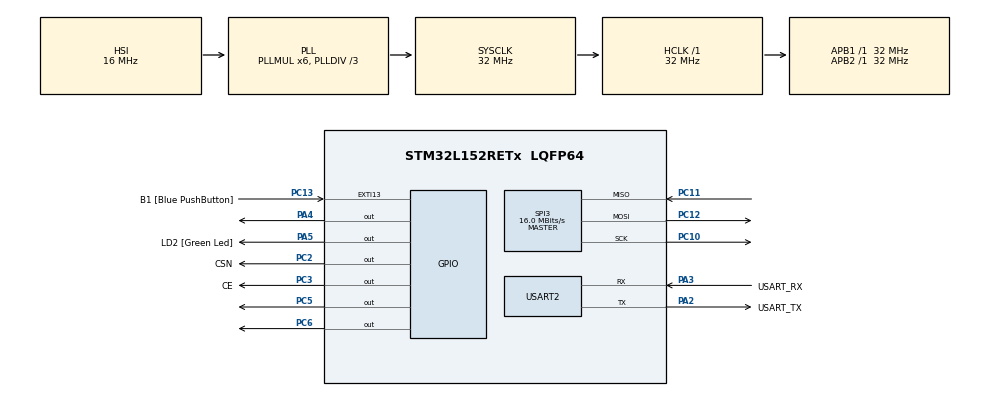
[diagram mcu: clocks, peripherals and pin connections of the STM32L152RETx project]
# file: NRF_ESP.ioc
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Mcu.Family=STM32L1
Mcu.Name=STM32L152RETx
Mcu.Package=LQFP64
NVIC.PriorityGroup=NVIC_PRIORITYGROUP_0
NVIC.SPI3_IRQn=true\:0\:0\:false\:false\:true\:true\:true\:true
PA13.GPIO_Label=TMS
PA13.Mode=Serial_Wire
PA13.Signal=SYS_JTMS-SWDIO
PA14.GPIO_Label=TCK
PA14.Mode=Serial_Wire
PA14.Signal=SYS_JTCK-SWCLK
PA2.GPIO_Label=USART_TX
PA2.Mode=Asynchronous
PA2.Signal=USART2_TX
PA3.GPIO_Label=USART_RX
PA3.Mode=Asynchronous
PA3.Signal=USART2_RX
PA4.Signal=GPIO_Output
PA5.GPIO_Label=LD2 [Green Led]
PA5.Signal=GPIO_Output
PB3.GPIO_Label=SWO
PB3.Signal=SYS_JTDO-TRACESWO
PC10.Mode=Full_Duplex_Master
PC10.Signal=SPI3_SCK
PC11.Mode=Full_Duplex_Master
PC11.Signal=SPI3_MISO
PC12.Mode=Full_Duplex_Master
PC12.Signal=SPI3_MOSI
PC13-WKUP2.GPIO_Label=B1 [Blue PushButton]
PC13-WKUP2.Signal=GPXTI13
PC14-OSC32_IN.Mode=LSE-External-Oscillator
PC14-OSC32_IN.Signal=RCC_OSC32_IN
PC15-OSC32_OUT.Mode=LSE-External-Oscillator
PC15-OSC32_OUT.Signal=RCC_OSC32_OUT
PC2.GPIO_Label=CSN
PC2.Signal=GPIO_Output
PC3.GPIO_Label=CE
PC3.Signal=GPIO_Output
PC5.Signal=GPIO_Output
PC6.Signal=GPIO_Output
PH0-OSC_IN.Mode=HSE-External-Clock-Source
PH0-OSC_IN.Signal=RCC_OSC_IN
PH1-OSC_OUT.Signal=RCC_OSC_OUT
ProjectManager.HeapSize=0x200
ProjectManager.StackSize=0x400
ProjectManager.TargetToolchain=STM32CubeIDE
RCC.48MHZClocksFreq_Value=48000000
RCC.AHBFreq_Value=32000000
RCC.APB1Freq_Value=32000000
RCC.APB1TimFreq_Value=32000000
RCC.APB2Freq_Value=32000000
RCC.APB2TimFreq_Value=32000000
RCC.HCLKFreq_Value=32000000
RCC.HSE_VALUE=8000000
RCC.HSI_VALUE=16000000
RCC.MSI_VALUE=2097000
RCC.PLLDIV=RCC_PLL_DIV3
RCC.PLLMUL=RCC_PLL_MUL6
RCC.RTCClockSelectionVirtual=RCC_RTCCLKSOURCE_LSE
RCC.SYSCLKFreq_VALUE=32000000
RCC.SYSCLKSource=RCC_SYSCLKSOURCE_PLLCLK
RCC.USBOutput=48000000
RCC.VCOOutputFreq_Value=96000000
SPI3.CalculateBaudRate=16.0 MBits/s
SPI3.Direction=SPI_DIRECTION_2LINES
SPI3.Mode=SPI_MODE_MASTER
SPI3.VirtualType=VM_MASTER
USART2.VirtualMode=VM_ASYNC
board=NUCLEO-L152RE

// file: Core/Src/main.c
/* USER CODE BEGIN Header */
/**
  ******************************************************************************
  * @file           : main.c
  * @brief          : Main program body
  ******************************************************************************
  * @attention
  *
  * Copyright (c) 2024 STMicroelectronics.
  * All rights reserved.
  *
  * This software is licensed under terms that can be found in the LICENSE file
  * in the root directory of this software component.
  * If no LICENSE file comes with this software, it is provided AS-IS.
  *
  ******************************************************************************
  */
/* USER CODE END Header */
#include "main.h"

/* USER CODE BEGIN Includes */
#include "NRF24L01.h"
#include "string.h"
/* USER CODE END Includes */

SPI_HandleTypeDef hspi3;

UART_HandleTypeDef huart2;

void SystemClock_Config(void);
static void MX_GPIO_Init(void);
static void MX_USART2_UART_Init(void);
static void MX_SPI3_Init(void);

/* USER CODE BEGIN 0 */

uint8_t data[50];

uint8_t TxAddress[] = {0xEE,0xDD,0xCC,0xBB,0xAA};
uint8_t TxData[] = "I am From STM32 World\n";

/* USER CODE END 0 */

int main(void)
{

  /* MCU Configuration--------------------------------------------------------*/

  /* Reset of all peripherals, Initializes the Flash interface and the Systick. */
  HAL_Init();

  /* Configure the system clock */
  SystemClock_Config();

  /* Initialize all configured peripherals */
  MX_GPIO_Init();
  MX_USART2_UART_Init();
  MX_SPI3_Init();
  /* USER CODE BEGIN 2 */
  NRF24_Init();

  NRF24_TxMode(TxAddress, 10);

  /* USER CODE END 2 */

  /* Infinite loop */
  while (1)
  {

    /* USER CODE BEGIN 3 */
	  	  if (NRF24_Transmit(TxData) == 1)
	  	  {
	  		  HAL_GPIO_TogglePin(LD2_GPIO_Port, LD2_Pin);
	  		  HAL_UART_Transmit(&huart2 ,TxData , sizeof(TxData) , 100 );
	  	  }

  		  HAL_GPIO_TogglePin(LD2_GPIO_Port, LD2_Pin);
  		  HAL_UART_Transmit(&huart2 ,TxData , sizeof(TxData) , 100 );

	  	  HAL_Delay(1000);

  }
  /* USER CODE END 3 */
}

void SystemClock_Config(void)
{
  RCC_OscInitTypeDef RCC_OscInitStruct = {0};
  RCC_ClkInitTypeDef RCC_ClkInitStruct = {0};

  /** Configure the main internal regulator output voltage
  */
  __HAL_PWR_VOLTAGESCALING_CONFIG(PWR_REGULATOR_VOLTAGE_SCALE1);

  /** Initializes the RCC Oscillators according to the specified parameters
  * in the RCC_OscInitTypeDef structure.
  */
  RCC_OscInitStruct.OscillatorType = RCC_OSCILLATORTYPE_HSI;
  RCC_OscInitStruct.HSIState = RCC_HSI_ON;
  RCC_OscInitStruct.HSICalibrationValue = RCC_HSICALIBRATION_DEFAULT;
  RCC_OscInitStruct.PLL.PLLState = RCC_PLL_ON;
  RCC_OscInitStruct.PLL.PLLSource = RCC_PLLSOURCE_HSI;
  RCC_OscInitStruct.PLL.PLLMUL = RCC_PLL_MUL6;
  RCC_OscInitStruct.PLL.PLLDIV = RCC_PLL_DIV3;
  if (HAL_RCC_OscConfig(&RCC_OscInitStruct) != HAL_OK)
  {
    Error_Handler();
  }

  /** Initializes the CPU, AHB and APB buses clocks
  */
  RCC_ClkInitStruct.ClockType = RCC_CLOCKTYPE_HCLK|RCC_CLOCKTYPE_SYSCLK
                              |RCC_CLOCKTYPE_PCLK1|RCC_CLOCKTYPE_PCLK2;
  RCC_ClkInitStruct.SYSCLKSource = RCC_SYSCLKSOURCE_PLLCLK;
  RCC_ClkInitStruct.AHBCLKDivider = RCC_SYSCLK_DIV1;
  RCC_ClkInitStruct.APB1CLKDivider = RCC_HCLK_DIV1;
  RCC_ClkInitStruct.APB2CLKDivider = RCC_HCLK_DIV1;

  if (HAL_RCC_ClockConfig(&RCC_ClkInitStruct, FLASH_LATENCY_1) != HAL_OK)
  {
    Error_Handler();
  }
}

static void MX_SPI3_Init(void)
{

  /* SPI3 parameter configuration*/
  hspi3.Instance = SPI3;
  hspi3.Init.Mode = SPI_MODE_MASTER;
  hspi3.Init.Direction = SPI_DIRECTION_2LINES;
  hspi3.Init.DataSize = SPI_DATASIZE_8BIT;
  hspi3.Init.CLKPolarity = SPI_POLARITY_LOW;
  hspi3.Init.CLKPhase = SPI_PHASE_1EDGE;
  hspi3.Init.NSS = SPI_NSS_SOFT;
  hspi3.Init.BaudRatePrescaler = SPI_BAUDRATEPRESCALER_2;
  hspi3.Init.FirstBit = SPI_FIRSTBIT_MSB;
  hspi3.Init.TIMode = SPI_TIMODE_DISABLE;
  hspi3.Init.CRCCalculation = SPI_CRCCALCULATION_DISABLE;
  hspi3.Init.CRCPolynomial = 10;
  if (HAL_SPI_Init(&hspi3) != HAL_OK)
  {
    Error_Handler();
  }

}

static void MX_USART2_UART_Init(void)
{

  huart2.Instance = USART2;
  huart2.Init.BaudRate = 115200;
  huart2.Init.WordLength = UART_WORDLENGTH_8B;
  huart2.Init.StopBits = UART_STOPBITS_1;
  huart2.Init.Parity = UART_PARITY_NONE;
  huart2.Init.Mode = UART_MODE_TX_RX;
  huart2.Init.HwFlowCtl = UART_HWCONTROL_NONE;
  huart2.Init.OverSampling = UART_OVERSAMPLING_16;
  if (HAL_UART_Init(&huart2) != HAL_OK)
  {
    Error_Handler();
  }

}

static void MX_GPIO_Init(void)
{
  GPIO_InitTypeDef GPIO_InitStruct = {0};

  /* GPIO Ports Clock Enable */
  __HAL_RCC_GPIOC_CLK_ENABLE();
  __HAL_RCC_GPIOH_CLK_ENABLE();
  __HAL_RCC_GPIOA_CLK_ENABLE();
  __HAL_RCC_GPIOB_CLK_ENABLE();

  /*Configure GPIO pin Output Level */
  HAL_GPIO_WritePin(GPIOC, CSN_Pin|CE_Pin|GPIO_PIN_5|GPIO_PIN_6, GPIO_PIN_RESET);

  /*Configure GPIO pin Output Level */
  HAL_GPIO_WritePin(GPIOA, GPIO_PIN_4|LD2_Pin, GPIO_PIN_RESET);

  /*Configure GPIO pin : B1_Pin */
  GPIO_InitStruct.Pin = B1_Pin;
  GPIO_InitStruct.Mode = GPIO_MODE_IT_RISING;
  GPIO_InitStruct.Pull = GPIO_NOPULL;
  HAL_GPIO_Init(B1_GPIO_Port, &GPIO_InitStruct);

  /*Configure GPIO pins : CSN_Pin CE_Pin PC5 PC6 */
  GPIO_InitStruct.Pin = CSN_Pin|CE_Pin|GPIO_PIN_5|GPIO_PIN_6;
  GPIO_InitStruct.Mode = GPIO_MODE_OUTPUT_PP;
  GPIO_InitStruct.Pull = GPIO_NOPULL;
  GPIO_InitStruct.Speed = GPIO_SPEED_FREQ_LOW;
  HAL_GPIO_Init(GPIOC, &GPIO_InitStruct);

  /*Configure GPIO pins : PA4 LD2_Pin */
  GPIO_InitStruct.Pin = GPIO_PIN_4|LD2_Pin;
  GPIO_InitStruct.Mode = GPIO_MODE_OUTPUT_PP;
  GPIO_InitStruct.Pull = GPIO_NOPULL;
  GPIO_InitStruct.Speed = GPIO_SPEED_FREQ_LOW;
  HAL_GPIO_Init(GPIOA, &GPIO_InitStruct);

}

void Error_Handler(void)
{
  /* USER CODE BEGIN Error_Handler_Debug */
  /* User can add his own implementation to report the HAL error return state */
  __disable_irq();
  while (1)
  {
	  HAL_GPIO_WritePin(GPIOB , LD2_Pin , GPIO_PIN_SET);
  }
  /* USER CODE END Error_Handler_Debug */
}
